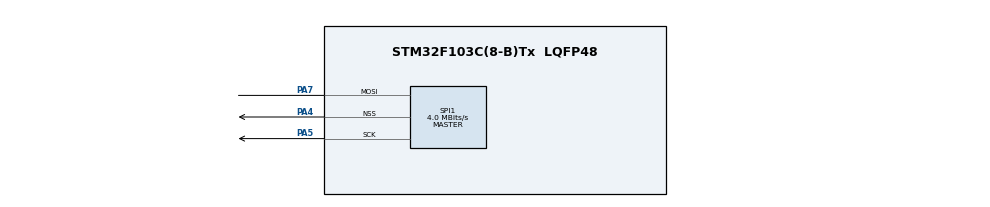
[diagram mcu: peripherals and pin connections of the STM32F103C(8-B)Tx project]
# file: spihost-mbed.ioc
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Mcu.Family=STM32F1
Mcu.Name=STM32F103C(8-B)Tx
Mcu.Package=LQFP48
NVIC.PriorityGroup=NVIC_PRIORITYGROUP_4
PA4.Mode=NSS_Signal_Hard_Output
PA4.Signal=SPI1_NSS
PA5.Mode=Simplex_Bidirectional_Master
PA5.Signal=SPI1_SCK
PA7.Mode=Simplex_Bidirectional_Master
PA7.Signal=SPI1_MOSI
ProjectManager.HeapSize=0x200
ProjectManager.StackSize=0x400
ProjectManager.TargetToolchain=EWARM V8.32
RCC.APB1Freq_Value=8000000
RCC.APB2Freq_Value=8000000
SPI1.CalculateBaudRate=4.0 MBits/s
SPI1.Direction=SPI_DIRECTION_1LINE
SPI1.Mode=SPI_MODE_MASTER
SPI1.VirtualNSS=VM_NSSHARD
SPI1.VirtualType=VM_MASTER
VP_SYS_VS_ND.Mode=No_Debug
board=custom

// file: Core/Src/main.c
/* USER CODE BEGIN Header */
/**
  ******************************************************************************
  * @file           : main.c
  * @brief          : Main program body
  ******************************************************************************
  * @attention
  *
  * <h2><center>&copy; Copyright (c) 2022 STMicroelectronics.
  * All rights reserved.</center></h2>
  *
  * This software component is licensed by ST under BSD 3-Clause license,
  * the "License"; You may not use this file except in compliance with the
  * License. You may obtain a copy of the License at:
  *                        opensource.org/licenses/BSD-3-Clause
  *
  ******************************************************************************
  */
/* USER CODE END Header */
#include "main.h"
#include "spi.h"
#include "gpio.h"

void SystemClock_Config(void);

/* USER CODE BEGIN 0 */
void SSD_Reset(){
    HAL_Delay(100);
    HAL_GPIO_WritePin(GPIOA,GPIO_PIN_3,GPIO_PIN_SET);
    HAL_Delay(100);
    HAL_GPIO_WritePin(GPIOA,GPIO_PIN_3,GPIO_PIN_RESET);
    HAL_Delay(100);
    HAL_GPIO_WritePin(GPIOA,GPIO_PIN_3,GPIO_PIN_SET);
    HAL_Delay(100);

    HAL_Delay(100);
    HAL_GPIO_WritePin(GPIOB,GPIO_PIN_0,GPIO_PIN_RESET);
    HAL_Delay(100);
    HAL_GPIO_WritePin(GPIOB,GPIO_PIN_0,GPIO_PIN_SET);
}
void SSD_SPI_Write(uint8_t *buf,int length){
    HAL_SPI_Transmit(&hspi1,buf,length,HAL_TIMEOUT);
}
void SSD_SPI_Read(int length, uint8_t *r){
    HAL_SPI_Receive(&hspi1,r,length,HAL_TIMEOUT);
}
void SSD_SPI_ReadWrite(uint8_t *buf, int length, uint16_t *r){
    uint16_t bufr[length];
    HAL_SPI_TransmitReceive(&hspi1,buf,bufr,length+2,HAL_TIMEOUT);
    volatile uint8_t byter0=0|bufr[length]>>1;
    volatile uint8_t byter1=0|((bufr[length]&0b000000001)<<7)|(bufr[length+1]>>2);
    volatile uint8_t byter2=0|((bufr[length+1]&0b000000011)<<6)|(bufr[length+2]>>3);
    r[0]=byter0;
    r[1]=byter1;
    r[2]=byter2;
}
uint16_t SSD_SPI_ReadReg(uint8_t reg){
    uint16_t tbuf[2];
    tbuf[0]=reg;
    tbuf[1]=0xfa;
    uint16_t rbuf[2];
    SSD_SPI_ReadWrite((uint8_t*)tbuf,2,(uint8_t*)rbuf);
    return rbuf[0]|rbuf[1]<<8;

}

void SSD_SPI_WriteReg(uint8_t reg,uint16_t data){
    uint16_t buf[3]={reg,1<<8|(data&0xff),1<<8|((data>>8)&0xff)};
    SSD_SPI_Write(buf,3);
}
void SSD_WriteMIPI(uint8_t reg,uint8_t data0,uint8_t data1,int length){
    SSD_SPI_WriteReg(0xbc,length);
    uint16_t tbuf[4];
    tbuf[0]=0x0bf, tbuf[1]=1<<8|reg; tbuf[2]=1<<8|data0; tbuf[3]=1<<8|data1;
    SSD_SPI_Write(&tbuf,length+1);
}
uint16_t SSD_ReadMIPI(uint8_t reg){
    SSD_SPI_WriteReg(0xb7,0x0382);
    SSD_SPI_WriteReg(0xbb,0x0004);
    SSD_SPI_WriteReg(0xc1,0x000a);
    SSD_SPI_WriteReg(0xc0,0x0100);
    SSD_SPI_WriteReg(0xbc,0x0051);
    SSD_SPI_WriteReg(0xbf,0x00c6);

    uint16_t tbuf[2];uint16_t rbuf[2];
    tbuf[0]=0xd4;tbuf[1]=0x1fa;tbuf[2]=0x100;
    SSD_SPI_Write(&tbuf,3);
    tbuf[0]=0xc6,tbuf[1]=0xfa;
    SSD_SPI_ReadWrite(&tbuf,2,&rbuf);
    return rbuf[0]|rbuf[1]<<8;
}
/* USER CODE END 0 */

int main(void)
{

  /* MCU Configuration--------------------------------------------------------*/

  /* Reset of all peripherals, Initializes the Flash interface and the Systick. */
  HAL_Init();

  /* Configure the system clock */
  SystemClock_Config();

  /* Initialize all configured peripherals */
  MX_GPIO_Init();
  MX_SPI1_Init();

  /* Infinite loop */
  /* USER CODE BEGIN WHILE */

    HAL_GPIO_WritePin(GPIOA,GPIO_PIN_4,GPIO_PIN_SET);
    HAL_Delay(1000);
    uint16_t buf[4];
    SSD_Reset();
  while (1)
  {
    /* USER CODE END WHILE */

    /* USER CODE BEGIN 3 */

      //SSD_Reset();

      volatile uint16_t result=SSD_SPI_ReadReg(0xb0);
      result;

      SSD_SPI_WriteReg(0xb9,0x0001);
      SSD_SPI_WriteReg(0xb7,0x0300);

      SSD_WriteMIPI(0xb0,0x04,0,2);
      SSD_WriteMIPI(0x00,0,0,1);
      SSD_WriteMIPI(0x00,0,0,1);
      SSD_WriteMIPI(0xd6,0x01,0,2);
      SSD_WriteMIPI(0x51,0x0f,0xff,3);
      SSD_WriteMIPI(0x53,0x04,0,2);
      SSD_WriteMIPI(0x29,0,0,1);
      SSD_WriteMIPI(0x11,0,0,1);

      SSD_SPI_WriteReg(0xb7,0x0309);
      SSD_SPI_WriteReg(0xee,0x0600);
      volatile uint16_t r=SSD_ReadMIPI(0x00);
      r=0|r;

  }
  /* USER CODE END 3 */
}

void SystemClock_Config(void)
{
  RCC_OscInitTypeDef RCC_OscInitStruct = {0};
  RCC_ClkInitTypeDef RCC_ClkInitStruct = {0};

  /** Initializes the RCC Oscillators according to the specified parameters
  * in the RCC_OscInitTypeDef structure.
  */
  RCC_OscInitStruct.OscillatorType = RCC_OSCILLATORTYPE_HSI;
  RCC_OscInitStruct.HSIState = RCC_HSI_ON;
  RCC_OscInitStruct.HSICalibrationValue = RCC_HSICALIBRATION_DEFAULT;
  RCC_OscInitStruct.PLL.PLLState = RCC_PLL_NONE;
  if (HAL_RCC_OscConfig(&RCC_OscInitStruct) != HAL_OK)
  {
    Error_Handler();
  }
  /** Initializes the CPU, AHB and APB buses clocks
  */
  RCC_ClkInitStruct.ClockType = RCC_CLOCKTYPE_HCLK|RCC_CLOCKTYPE_SYSCLK
                              |RCC_CLOCKTYPE_PCLK1;
  RCC_ClkInitStruct.SYSCLKSource = RCC_SYSCLKSOURCE_HSI;
  RCC_ClkInitStruct.AHBCLKDivider = RCC_SYSCLK_DIV1;
  RCC_ClkInitStruct.APB1CLKDivider = RCC_HCLK_DIV1;

  if (HAL_RCC_ClockConfig(&RCC_ClkInitStruct, FLASH_LATENCY_0) != HAL_OK)
  {
    Error_Handler();
  }
}

void Error_Handler(void)
{
  __disable_irq();
  while (1)
  {
  }
}

/************************ (C) COPYRIGHT STMicroelectronics *****END OF FILE****/
